VERSION ""

NS_ :

BS_:

BU_: ECU_3 ECU_2 ECU_1

BO_ 86 Obstacles_sensor_action: 1 ECU_2
 SG_ TrunkAction : 0|8@1- (1,0) [0|0] "" Vector__XXX

BO_ 67 Foot_sensor_action: 8 ECU_2

BO_ 52 Fob_sensor_action: 8 ECU_2

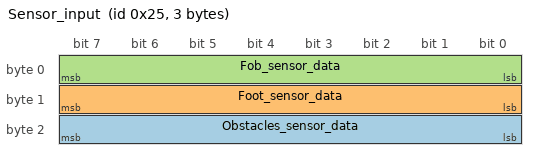
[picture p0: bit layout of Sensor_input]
BO_ 37 Sensor_input: 3 ECU_1
 SG_ Obstacles_sensor_data : 16|8@1- (1,0) [0|0] "" Vector__XXX
 SG_ Foot_sensor_data : 8|8@1- (1,0) [0|0] "" Vector__XXX
 SG_ Fob_sensor_data : 0|8@1- (1,0) [0|0] "" Vector__XXX

BA_DEF_  "BusType" STRING ;
BA_DEF_DEF_  "BusType" "CAN";
